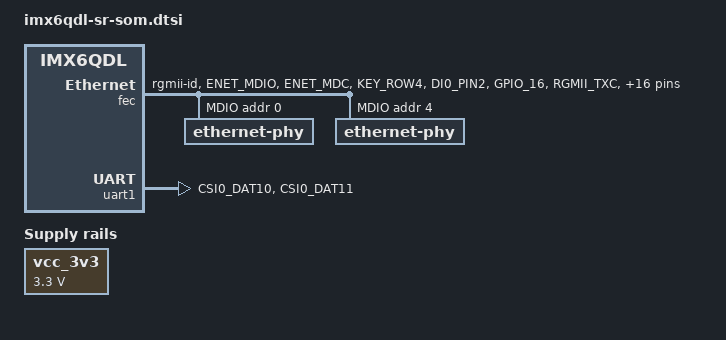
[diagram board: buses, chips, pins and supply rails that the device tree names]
#include <dt-bindings/gpio/gpio.h>
/ {
	vcc_3v3: regulator-vcc-3v3 {
		compatible = "regulator-fixed";
		regulator-always-on;
		regulator-name = "vcc_3v3";
		regulator-min-microvolt = <3300000>;
		regulator-max-microvolt = <3300000>;
	};
};
&fec {
	pinctrl-names = "default";
	pinctrl-0 = <&pinctrl_microsom_enet_ar8035>;
	phy-mode = "rgmii-id";
	phy-reset-duration = <10>;
	phy-reset-gpios = <&gpio4 15 GPIO_ACTIVE_LOW>;
	status = "okay";
	mdio {
		#address-cells = <1>;
		#size-cells = <0>;
		ethernet-phy@0 {
			reg = <0>;
			qca,clk-out-frequency = <125000000>;
			qca,smarteee-tw-us-1g = <24>;
		};
		ethernet-phy@4 {
			reg = <4>;
			qca,clk-out-frequency = <125000000>;
			qca,smarteee-tw-us-1g = <24>;
		};
		ethernet-phy@1 {
			reg = <1>;
			adi,phy-output-clock = "125mhz-free-running";
			status = "disabled";
		};
	};
};
&iomuxc {
	microsom {
		pinctrl_microsom_enet_ar8035: microsom-enet-ar8035 {
			fsl,pins = <
				MX6QDL_PAD_ENET_MDIO__ENET_MDIO		0x1b8b0
				MX6QDL_PAD_ENET_MDC__ENET_MDC		0x1b0b0
				MX6QDL_PAD_KEY_ROW4__GPIO4_IO15		0x130b0
				MX6QDL_PAD_DI0_PIN2__GPIO4_IO18		0x1b0b0
				MX6QDL_PAD_GPIO_16__ENET_REF_CLK	0x4001b0b0
				MX6QDL_PAD_RGMII_TXC__RGMII_TXC		0x13030
				MX6QDL_PAD_RGMII_TD0__RGMII_TD0		0x1b030
				MX6QDL_PAD_RGMII_TD1__RGMII_TD1		0x1b030
				MX6QDL_PAD_RGMII_TD2__RGMII_TD2		0x1b030
				MX6QDL_PAD_RGMII_TD3__RGMII_TD3		0x1b030
				MX6QDL_PAD_RGMII_TX_CTL__RGMII_TX_CTL	0x1b030
				MX6QDL_PAD_ENET_REF_CLK__ENET_TX_CLK	0x0a0b1
				MX6QDL_PAD_RGMII_RXC__RGMII_RXC		0x1b030
				MX6QDL_PAD_RGMII_RD0__RGMII_RD0		0x13030
				MX6QDL_PAD_RGMII_RD1__RGMII_RD1		0x13030
				MX6QDL_PAD_RGMII_RD2__RGMII_RD2		0x1b030
				MX6QDL_PAD_RGMII_RD3__RGMII_RD3		0x1b030
				MX6QDL_PAD_RGMII_RX_CTL__RGMII_RX_CTL	0x13030
				MX6QDL_PAD_ENET_CRS_DV__GPIO1_IO25	0x03000
				MX6QDL_PAD_ENET_RXD0__GPIO1_IO27	0x03000
				MX6QDL_PAD_ENET_RXD1__GPIO1_IO26	0x03000
			>;
		};
		pinctrl_microsom_uart1: microsom-uart1 {
			fsl,pins = <
				MX6QDL_PAD_CSI0_DAT10__UART1_TX_DATA	0x1b0b1
				MX6QDL_PAD_CSI0_DAT11__UART1_RX_DATA	0x1b0b1
			>;
		};
	};
};
&uart1 {
	pinctrl-names = "default";
	pinctrl-0 = <&pinctrl_microsom_uart1>;
	status = "okay";
};
